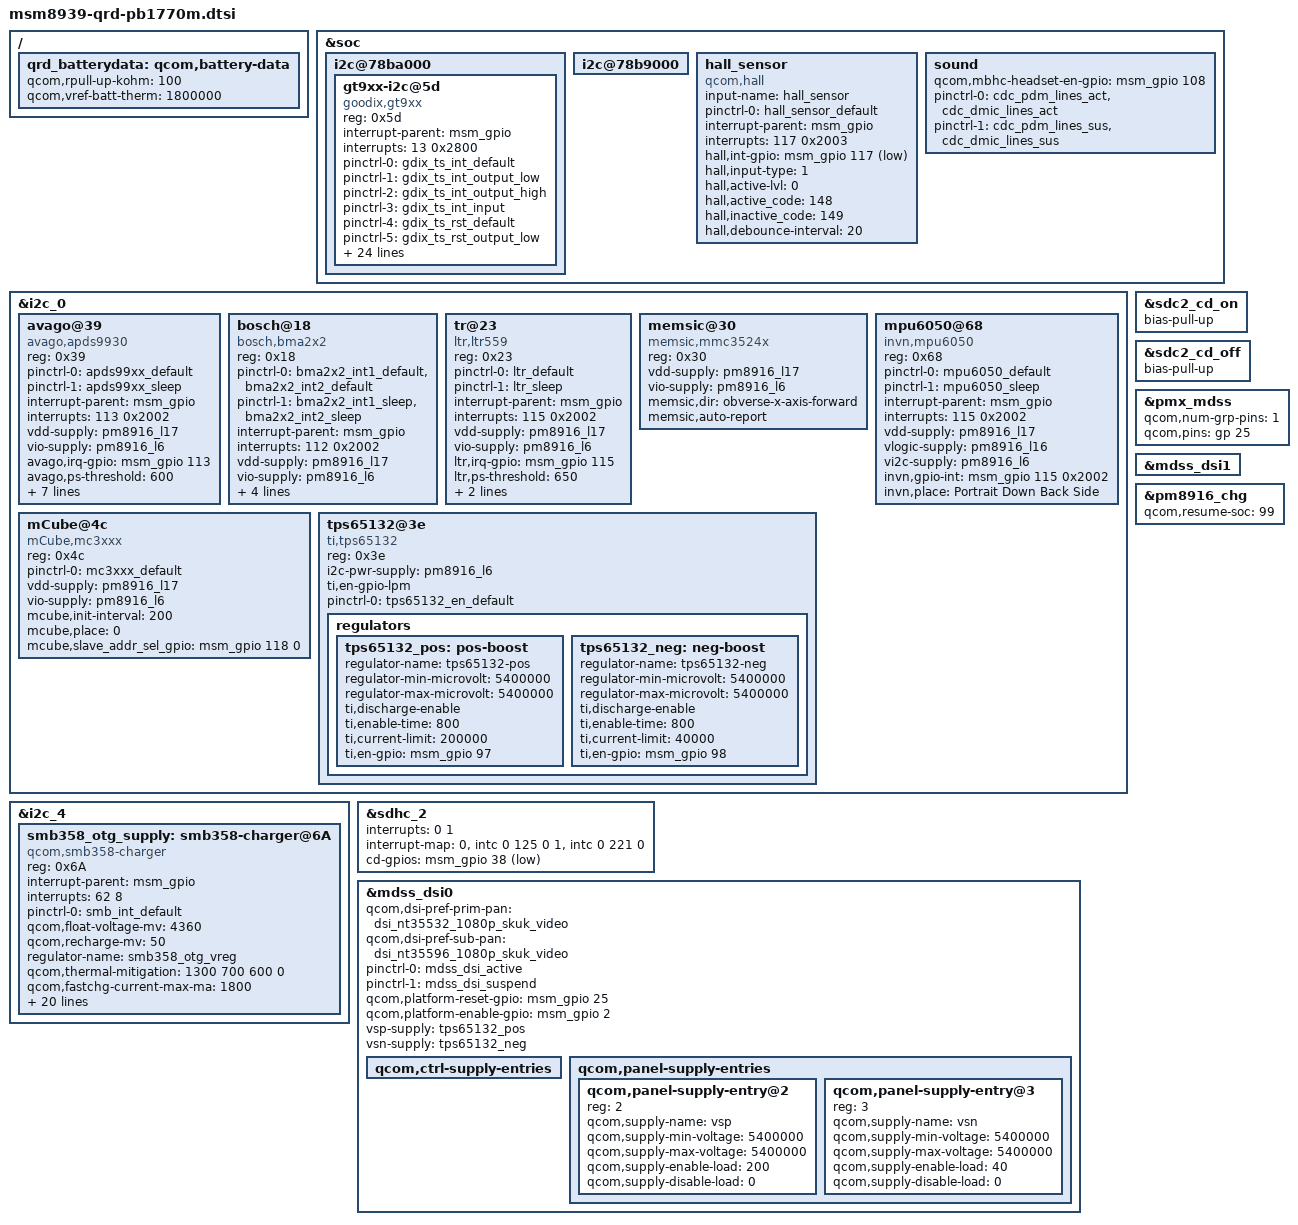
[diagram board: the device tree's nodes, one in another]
/* Copyright (c) 2020, The Linux Foundation. All rights reserved.
*  Copyright (c) 2015, Lenovo.
*  Copyright (c) 2020, the_shahnawaz_sheikh (sheikhshahnawaz41299).
*
* This program is free software; you can redistribute it and/or modify
* it under the terms of the GNU General Public License version 2 and
* only version 2 as published by the Free Software Foundation.
*
* This program is distributed in the hope that it will be useful,
* but WITHOUT ANY WARRANTY; without even the implied warranty of
* MERCHANTABILITY or FITNESS FOR A PARTICULAR PURPOSE.  See the
* GNU General Public License for more details.
*/

#include "msm8939-pinctrl-pb1770m.dtsi"
#include "msm8939-common-pb1770m.dtsi"
#include "dsi-panel-nt35596-1080p-skuk-video.dtsi"
#include "dsi-panel-nt35532-1080p-skuk-video.dtsi"
#include "msm8939-camera-pb1770m.dtsi"

&soc {
	
	i2c@78ba000 { /* BLSP1 QUP6 */
	    
		/delete-node/ nfc-nci@e;
		
		gt9xx-i2c@5d {
			compatible = "goodix,gt9xx";
			reg = <0x5d>;
			interrupt-parent = <&msm_gpio>;
			interrupts = <13 0x2800>;
			pinctrl-names = "gdix_ts_int_default",
				"gdix_ts_int_output_low",
				"gdix_ts_int_output_high",
				"gdix_ts_int_input",
				"gdix_ts_rst_default",
				"gdix_ts_rst_output_low",
				"gdix_ts_rst_output_high",
				"gdix_ts_rst_input";
			pinctrl-0 = <&gdix_ts_int_default>;
			pinctrl-1 = <&gdix_ts_int_output_low>;
			pinctrl-2 = <&gdix_ts_int_output_high>;
			pinctrl-3 = <&gdix_ts_int_input>;
			pinctrl-4 = <&gdix_ts_rst_default>;
			pinctrl-5 = <&gdix_ts_rst_output_low>;
			pinctrl-6 = <&gdix_ts_rst_output_high>;
			pinctrl-7 = <&gdix_ts_rst_input>;
			reset-gpios = <&msm_gpio 12 0x00>;
			irq-gpios = <&msm_gpio 13 0x2800>;
			irq-flags = <1>;
			vdd_ana-supply = <&pm8916_l17>;
			vcc_i2c-supply = <&pm8916_l6>;
			touchscreen-max-id = <5>;
			touchscreen-size-x = <1080>;
			touchscreen-size-y = <1920>;
			touchscreen-max-w = <512>;
			touchscreen-max-p = <512>;
			touchscreen-key-map = <139>, <102>, <158>; /*KEY_BACK=158，KEY_HOMEPAGE=102, KEY_MENU=139*/
			goodix,slide-wakeup = <1>;
			goodix,type-a-report = <0>;
			goodix,driver-send-cfg = <1>;
			goodix,resume-in-workqueue = <0>;
			goodix,int-sync = <1>;
			goodix,swap-x2y = <0>;
			goodix,esd-protect = <1>;
			goodix,auto-update = <0>;
			goodix,auto-update-cfg = <0>;
			goodix,power-off-sleep = <1>;
			goodix,pen-suppress-finger = <0>;
		};
	};
	
	i2c@78b9000 { /* BLSP1 QUP5 */
	    
		/delete-node/ focaltech@38;
	};
	
	
	hall_sensor {
		compatible = "qcom,hall";
		input-name = "hall_sensor";

		pinctrl-names = "s5712_default";
		pinctrl-0 = <&hall_sensor_default>;
		interrupt-parent = <&msm_gpio>;
		interrupts = <117 0x2003>;//<117 0x2002>;
		hall,int-gpio = <&msm_gpio 117 0x2003>;
		hall,input-type = <1>;
		hall,active-lvl = <0>;
		hall,active_code = <148>;
		hall,inactive_code = <149>;
		hall,debounce-interval = <20>;
	};
	
	sound {
		qcom,mbhc-headset-en-gpio = <&msm_gpio 108 0>;
		pinctrl-0 = <&cdc_pdm_lines_act &cdc_dmic_lines_act>;
		pinctrl-1 = <&cdc_pdm_lines_sus &cdc_dmic_lines_sus>;
	};
	
	
};

&i2c_0 { /* BLSP1 QUP2 */
	avago@39 { /* Ambient light and proximity sensor */
		compatible = "avago,apds9930";
		reg = <0x39>;
		pinctrl-names = "default","sleep";
		pinctrl-0 = <&apds99xx_default>;
		pinctrl-1 = <&apds99xx_sleep>;
		interrupt-parent = <&msm_gpio>;
		interrupts = <113 0x2002>;
		vdd-supply = <&pm8916_l17>;
		vio-supply = <&pm8916_l6>;
		avago,irq-gpio = <&msm_gpio 113 0x2002>;
		avago,ps-threshold = <600>;
		avago,ps-hysteresis-threshold = <500>;
		avago,ps-pulse = <8>;
		avago,ps-pgain = <0>;
		avago,als-B = <186>;
		avago,als-C = <75>;
		avago,als-D = <129>;
		avago,ga-value = <560>;
	};

	bosch@18 { /* Accelerometer sensor */
		compatible = "bosch,bma2x2";
		reg = <0x18>;
		pinctrl-names = "bma_default","bma_sleep";
		pinctrl-0 = <&bma2x2_int1_default &bma2x2_int2_default>;
		pinctrl-1 = <&bma2x2_int1_sleep &bma2x2_int2_sleep>;
		interrupt-parent = <&msm_gpio>;
		interrupts = <112 0x2002>;
		vdd-supply = <&pm8916_l17>;
		vio-supply = <&pm8916_l6>;
		bosch,init-interval = <200>;
		/delete-property/ bosch,place;
		bosch,place = <6>;//<2>;
		bosch,gpio-int1 = <&msm_gpio 112 0x2002>;
		bosch,gpio-int2 = <&msm_gpio 114 0x2002>;
	};
	
	tr@23 { /* Ambient light and proximity sensor */ 
                        compatible = "ltr,ltr559"; 
                        reg = <0x23>; 
                        pinctrl-names = "default","sleep"; 
                        pinctrl-0 = <&ltr_default>; 
                        pinctrl-1 = <&ltr_sleep>; 
                        interrupt-parent = <&msm_gpio>; 
                        interrupts = <115 0x2002>; 
                        vdd-supply = <&pm8916_l17>; 
                        vio-supply = <&pm8916_l6>; 
                        ltr,irq-gpio = <&msm_gpio 115 0x2002>; 
                        ltr,ps-threshold = <650>; 
                        ltr,ps-hysteresis-threshold = <500>; 
                        ltr,als-polling-time = <200>; 
        }; 
		
	/delete-node/ memsic@30;

	memsic@30 { /* Magnetic field sensor */
		compatible = "memsic,mmc3524x";
		reg = <0x30>;
		vdd-supply = <&pm8916_l17>;
		vio-supply = <&pm8916_l6>;
		memsic,dir = "obverse-x-axis-forward";
		memsic,auto-report;
	};
	
	mpu6050@68 { /* Gyroscope and accelerometer sensor combo */
		compatible = "invn,mpu6050";
		reg = <0x68>;
		pinctrl-names = "mpu_default","mpu_sleep";
		pinctrl-0 = <&mpu6050_default>;
		pinctrl-1 = <&mpu6050_sleep>;
		interrupt-parent = <&msm_gpio>;
		interrupts = <115 0x2002>;
		vdd-supply = <&pm8916_l17>;
		vlogic-supply = <&pm8916_l16>;
		vi2c-supply = <&pm8916_l6>;
		invn,gpio-int = <&msm_gpio 115 0x2002>;
		invn,place = "Portrait Down Back Side";
	};
	
	mCube@4c {
			compatible = "mCube,mc3xxx";
			reg = <0x4c>;
			pinctrl-names = "default";
			pinctrl-0 = <&mc3xxx_default>;
			vdd-supply = <&pm8916_l17>;
			vio-supply = <&pm8916_l6>;
			mcube,init-interval = <200>;
			mcube,place = <0>;
			mcube,slave_addr_sel_gpio = <&msm_gpio 118 0>;
		};
	
	tps65132@3e {
		compatible = "ti,tps65132";
		reg = <0x3e>;
		i2c-pwr-supply = <&pm8916_l6>;
		ti,en-gpio-lpm;
		pinctrl-names = "default";
		pinctrl-0 = <&tps65132_en_default>;

		regulators {
			tps65132_pos: pos-boost {
				regulator-name = "tps65132-pos";
				regulator-min-microvolt = <5400000>;
				regulator-max-microvolt = <5400000>;
				ti,discharge-enable;
				ti,enable-time = <800>;
				ti,current-limit = <200000>;
				ti,en-gpio = <&msm_gpio 97 0>;
			};

			tps65132_neg: neg-boost {
				regulator-name = "tps65132-neg";
				regulator-min-microvolt = <5400000>;
				regulator-max-microvolt = <5400000>;
				ti,discharge-enable;
				ti,enable-time = <800>;
				ti,current-limit = <40000>;
				ti,en-gpio = <&msm_gpio 98 0>;
			};
		};
	};
	
};

&i2c_4 {
	smb358_otg_supply: smb358-charger@6A {
			compatible = "qcom,smb358-charger";
			reg = <0x6A>;
			interrupt-parent = <&msm_gpio>;
			interrupts = <62 8>;
			pinctrl-names = "default";
			pinctrl-0 = <&smb_int_default>;

			qcom,float-voltage-mv = <4360>;
			qcom,recharge-mv = <50>;
			//qcom,recharge-disabled;
			regulator-name = "smb358_otg_vreg";
			qcom,thermal-mitigation = <1300 700 600 0>;
			qcom,fastchg-current-max-ma = <1800>;

			qcom,disable-apsd;
			qcom,bms-psy-name = "bms";
			/* qcom,iterm-disabled; */
			qcom,iterm-ma = <100>;
			qcom,bms-controlled-charging;
			qcom,chg-inhibit-disabled;
			qcom,chg-vadc = <&pm8916_vadc>;
			qcom,chg-adc_tm = <&pm8916_adc_tm>;
			//qcom,vcc-i2c-supply = <&pm8916_l5>;
			qcom,irq-gpio = <&msm_gpio 62 2>;
			
			/* Chg LED */
			
			qcom,chg-green = <&msm_gpio 119 2>;
		    qcom,chg-blue = <&msm_gpio 8 2>;

			qcom,using-pmic-therm;
			qcom,hot-bat-decidegc = <500>;
			qcom,cold-bat-decidegc = <0>;
			qcom,bat-present-decidegc = <200>;
			/*
			 * Below properties are used for enable JEITA
			 */
			qcom,warm-bat-decidegc = <450>;
			qcom,cool-bat-decidegc = <150>;
			qcom,warm-bat-ma = <1000>;
			qcom,cool-bat-ma = <720>;
			qcom,warm-bat-mv = <4100>;
			qcom,cool-bat-mv = <4350>;
			status = "ok";
		};
};

&sdc2_cd_on {
	/delete-property/ bias-pull-down;
	bias-pull-up;
};

&sdc2_cd_off {
	/delete-property/ bias-pull-down;
	bias-pull-up;
};

&sdhc_2 {
  /delete-property/	qcom,nonhotplug;
	interrupts = <0 1>;
	interrupt-map = <0 &intc 0 125 0
		1 &intc 0 221 0>;
	interrupt-names = "hc_irq", "pwr_irq";
    /delete-property/ cd-gpios;
	cd-gpios = <&msm_gpio 38 0x1>;
};	

&pmx_mdss {
	qcom,num-grp-pins = <1>;
	qcom,pins = <&gp 25>;
};

&mdss_dsi0 {
	qcom,dsi-pref-prim-pan = <&dsi_nt35532_1080p_skuk_video>;
	qcom,dsi-pref-sub-pan = <&dsi_nt35596_1080p_skuk_video>;
	pinctrl-names = "mdss_default", "mdss_sleep";
	pinctrl-0 = <&mdss_dsi_active>;
	pinctrl-1 = <&mdss_dsi_suspend>;
	
	/delete-property/ vdda-supply;
	/delete-property/ vdd-supply;
	/delete-property/ qcom,dsi-clk-ln-recovery;

	qcom,platform-reset-gpio = <&msm_gpio 25 0>;
	qcom,platform-enable-gpio = <&msm_gpio 2 0>;
	/delete-property/ qcom,platform-te-gpio;
	/delete-property/ qcom,platform-bklight-en-gpio;

	vsp-supply = <&tps65132_pos>;
	vsn-supply = <&tps65132_neg>;

	qcom,ctrl-supply-entries {
		/delete-node/ qcom,ctrl-supply-entry@0;
	};

	qcom,panel-supply-entries {
		/delete-node/qcom,panel-supply-entry@0;

		qcom,panel-supply-entry@2 {
			reg = <2>;
			qcom,supply-name = "vsp";
			qcom,supply-min-voltage = <5400000>;
			qcom,supply-max-voltage = <5400000>;
			qcom,supply-enable-load = <200>;
			qcom,supply-disable-load = <0>;
		};

		qcom,panel-supply-entry@3 {
			reg = <3>;
			qcom,supply-name = "vsn";
			qcom,supply-min-voltage = <5400000>;
			qcom,supply-max-voltage = <5400000>;
			qcom,supply-enable-load = <40>;
			qcom,supply-disable-load = <0>;
		};
	};

};

&mdss_dsi1 {
    /delete-property/ qcom,dsi-clk-ln-recovery;
};

&pm8916_chg { 
   qcom,resume-soc = <99>;
};



/ {
	qrd_batterydata: qcom,battery-data {
		qcom,rpull-up-kohm = <100>;
		qcom,vref-batt-therm = <1800000>;

		#include "batterydata-qrd-skuk-scud-4v35-3600mah.dtsi"
		#include "batterydata-qrd-skuk-xwd-4v35-3500mah.dtsi"
	};
};

